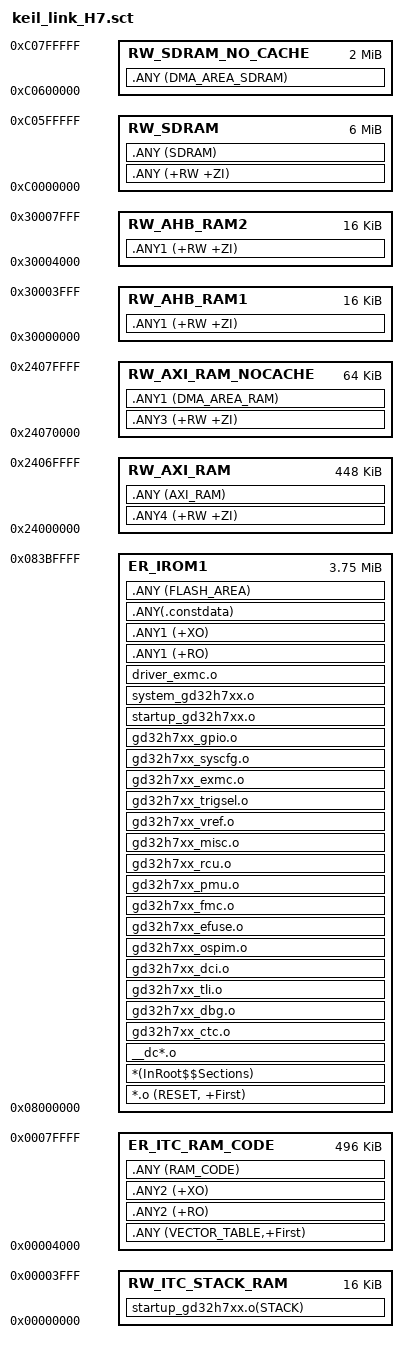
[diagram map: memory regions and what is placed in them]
; *************************************************************
; *** Scatter-Loading Description File generated by uVision ***
; *************************************************************

LR_IROM1 0x08000000 0x003C0000  {    ; load region size_region
  ER_IROM1 0x08000000 0x003C0000  {  ; load address = execution address
    *.o (RESET, +First)
    *(InRoot$$Sections)
    __dc*.o;     
;    __dczerorl2.o  
;    iusefp.o
;    llushr.o
;    llshl.o
;    dscalb.o
;    errno.o
;    dunder.o
;    poly.o
;    fpclassify.o  
;    qnan.o 
;    
;    anon$$obj.o  
;    mc_w.l 
;    anon$$obj.o  
;    Veneer$$Code
;    
;    uidiv.o
;    uldiv.o
;    dadd.o
;    dmul.o
;    ddiv.o
;    dfixul.o
;    
;    cdrcmple.o
;    llsshr.o
;    depilogue.o
;    __dczerorl.o
    gd32h7xx_ctc.o
    gd32h7xx_dbg.o
    gd32h7xx_tli.o
    gd32h7xx_dci.o    
    gd32h7xx_ospim.o
    gd32h7xx_efuse.o
    
    gd32h7xx_fmc.o    
    gd32h7xx_pmu.o
    gd32h7xx_rcu.o    
    gd32h7xx_misc.o
    gd32h7xx_vref.o
    gd32h7xx_trigsel.o    
    gd32h7xx_exmc.o 
    gd32h7xx_syscfg.o 
    gd32h7xx_gpio.o
    startup_gd32h7xx.o
    system_gd32h7xx.o   
    
    driver_exmc.o  
    
    .ANY1 (+RO)
    .ANY1 (+XO)
    .ANY(.constdata)
    .ANY (FLASH_AREA)     
  }
  
  RW_ITC_STACK_RAM (0) 0x0004000 {  ; RW data
    startup_gd32h7xx.o(STACK) 
  }
  
  
  ER_ITC_RAM_CODE (0+0x0004000) (0x00080000-0x0004000)  {  ; RW data 
    .ANY (VECTOR_TABLE,+First)    
    .ANY2 (+RO)
    .ANY2 (+XO)
    .ANY (RAM_CODE) 
;    .ANY2 (+RW +ZI) 
  }
  
;  RW_ITC_STACK_RAM (0x00080000-0x0004000) 0x0004000 {  ; RW data
;    startup_gd32h7xx.o(STACK) 
;  }  
  
  RW_AXI_RAM 0x24000000 0x00070000  {  ; RW data
    .ANY4 (+RW +ZI)
    .ANY (AXI_RAM) 
  }
  
  RW_AXI_RAM_NOCACHE 0x24070000 0x00010000  {  ; RW data
    .ANY3 (+RW +ZI)
    .ANY1 (DMA_AREA_RAM)    
  }
  
  RW_AHB_RAM1 0x30000000 0x0004000  {  ; RW data
    .ANY1 (+RW +ZI)
  }  
  RW_AHB_RAM2 0x30004000 0x0004000  {  ; RW data
    .ANY1 (+RW +ZI)
  }   
  RW_SDRAM 0xC0000000 0x600000  {  ; RW data
    .ANY (+RW +ZI)
    .ANY (SDRAM)
  }
  RW_SDRAM_NO_CACHE 0xC0600000 0x200000  {  ; RW data
    .ANY (DMA_AREA_SDRAM)
  }   
}

